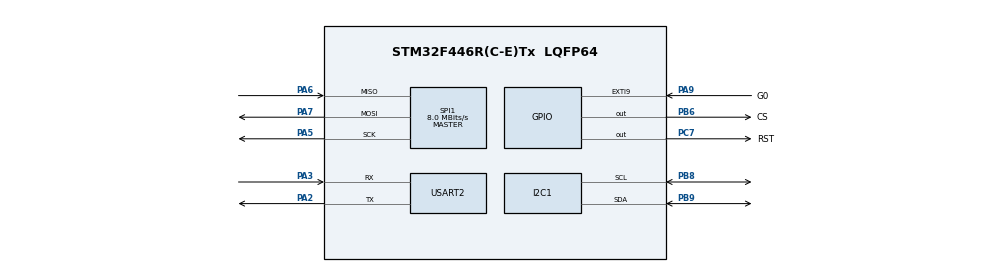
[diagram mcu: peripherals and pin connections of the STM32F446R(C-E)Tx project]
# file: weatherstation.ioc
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Dma.Request0=SPI1_TX
Dma.SPI1_TX.0.Direction=DMA_MEMORY_TO_PERIPH
Dma.SPI1_TX.0.FIFOMode=DMA_FIFOMODE_DISABLE
Dma.SPI1_TX.0.Instance=DMA2_Stream3
Dma.SPI1_TX.0.MemDataAlignment=DMA_MDATAALIGN_BYTE
Dma.SPI1_TX.0.MemInc=DMA_MINC_ENABLE
Dma.SPI1_TX.0.Mode=DMA_NORMAL
Dma.SPI1_TX.0.PeriphDataAlignment=DMA_PDATAALIGN_BYTE
Dma.SPI1_TX.0.PeriphInc=DMA_PINC_DISABLE
Dma.SPI1_TX.0.Priority=DMA_PRIORITY_LOW
Mcu.Family=STM32F4
Mcu.Name=STM32F446R(C-E)Tx
Mcu.Package=LQFP64
NVIC.DMA2_Stream3_IRQn=true\:0\:0\:false\:false\:true\:false\:true\:true
NVIC.EXTI9_5_IRQn=true\:5\:0\:true\:false\:true\:true\:true\:true
NVIC.PriorityGroup=NVIC_PRIORITYGROUP_4
NVIC.SPI1_IRQn=true\:0\:0\:false\:false\:true\:true\:true\:true
NVIC.TIM6_DAC_IRQn=true\:15\:0\:false\:false\:true\:false\:true\:true
NVIC.TimeBase=TIM6_DAC_IRQn
NVIC.TimeBaseIP=TIM6
PA2.Mode=Asynchronous
PA2.Signal=USART2_TX
PA3.Mode=Asynchronous
PA3.Signal=USART2_RX
PA5.Mode=Full_Duplex_Master
PA5.Signal=SPI1_SCK
PA6.Mode=Full_Duplex_Master
PA6.Signal=SPI1_MISO
PA7.Mode=Full_Duplex_Master
PA7.Signal=SPI1_MOSI
PA9.GPIO_Label=G0
PA9.Signal=GPXTI9
PB6.GPIO_Label=CS
PB6.PinState=GPIO_PIN_SET
PB6.Signal=GPIO_Output
PB8.Mode=I2C
PB8.Signal=I2C1_SCL
PB9.Mode=I2C
PB9.Signal=I2C1_SDA
PC7.GPIO_Label=RST
PC7.PinState=GPIO_PIN_SET
PC7.Signal=GPIO_Output
ProjectManager.HeapSize=0x200
ProjectManager.StackSize=0x400
ProjectManager.TargetToolchain=CMake
RCC.CortexFreq_Value=16000000
RCC.USBFreq_Value=96000000
RCC.VCOOutputFreq_Value=192000000
SPI1.CalculateBaudRate=8.0 MBits/s
SPI1.Direction=SPI_DIRECTION_2LINES
SPI1.Mode=SPI_MODE_MASTER
SPI1.VirtualType=VM_MASTER
USART2.VirtualMode=VM_ASYNC
VP_SYS_VS_tim6.Mode=TIM6
board=custom

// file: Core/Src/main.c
/* USER CODE BEGIN Header */
/**
  ******************************************************************************
  * @file           : main.c
  * @brief          : Main program body
  ******************************************************************************
  * @attention
  *
  * Copyright (c) 2026 STMicroelectronics.
  * All rights reserved.
  *
  * This software is licensed under terms that can be found in the LICENSE file
  * in the root directory of this software component.
  * If no LICENSE file comes with this software, it is provided AS-IS.
  *
  ******************************************************************************
  */
/* USER CODE END Header */
#include "main.h"

/* USER CODE BEGIN Includes */
#include "main_ws.h"
/* USER CODE END Includes */

I2C_HandleTypeDef hi2c1;

SPI_HandleTypeDef hspi1;
DMA_HandleTypeDef hdma_spi1_tx;

UART_HandleTypeDef huart2;

void SystemClock_Config(void);
static void MX_GPIO_Init(void);
static void MX_DMA_Init(void);
static void MX_I2C1_Init(void);
static void MX_USART2_UART_Init(void);
static void MX_SPI1_Init(void);

int main(void)
{

  /* MCU Configuration--------------------------------------------------------*/

  /* Reset of all peripherals, Initializes the Flash interface and the Systick. */
  HAL_Init();

  /* Configure the system clock */
  SystemClock_Config();

  /* Initialize all configured peripherals */
  MX_GPIO_Init();
  MX_DMA_Init();
  MX_I2C1_Init();
  MX_USART2_UART_Init();
  MX_SPI1_Init();
  /* USER CODE BEGIN 2 */
  main_ws();

  /* USER CODE END 2 */

  /* Infinite loop */
  while (1)
  {

  }
}

void SystemClock_Config(void)
{
  RCC_OscInitTypeDef RCC_OscInitStruct = {0};
  RCC_ClkInitTypeDef RCC_ClkInitStruct = {0};

  /** Configure the main internal regulator output voltage
  */
  __HAL_RCC_PWR_CLK_ENABLE();
  __HAL_PWR_VOLTAGESCALING_CONFIG(PWR_REGULATOR_VOLTAGE_SCALE3);

  /** Initializes the RCC Oscillators according to the specified parameters
  * in the RCC_OscInitTypeDef structure.
  */
  RCC_OscInitStruct.OscillatorType = RCC_OSCILLATORTYPE_HSI;
  RCC_OscInitStruct.HSIState = RCC_HSI_ON;
  RCC_OscInitStruct.HSICalibrationValue = RCC_HSICALIBRATION_DEFAULT;
  RCC_OscInitStruct.PLL.PLLState = RCC_PLL_NONE;
  if (HAL_RCC_OscConfig(&RCC_OscInitStruct) != HAL_OK)
  {
    Error_Handler();
  }

  /** Initializes the CPU, AHB and APB buses clocks
  */
  RCC_ClkInitStruct.ClockType = RCC_CLOCKTYPE_HCLK|RCC_CLOCKTYPE_SYSCLK
                              |RCC_CLOCKTYPE_PCLK1|RCC_CLOCKTYPE_PCLK2;
  RCC_ClkInitStruct.SYSCLKSource = RCC_SYSCLKSOURCE_HSI;
  RCC_ClkInitStruct.AHBCLKDivider = RCC_SYSCLK_DIV1;
  RCC_ClkInitStruct.APB1CLKDivider = RCC_HCLK_DIV1;
  RCC_ClkInitStruct.APB2CLKDivider = RCC_HCLK_DIV1;

  if (HAL_RCC_ClockConfig(&RCC_ClkInitStruct, FLASH_LATENCY_0) != HAL_OK)
  {
    Error_Handler();
  }
}

static void MX_I2C1_Init(void)
{

  hi2c1.Instance = I2C1;
  hi2c1.Init.ClockSpeed = 100000;
  hi2c1.Init.DutyCycle = I2C_DUTYCYCLE_2;
  hi2c1.Init.OwnAddress1 = 0;
  hi2c1.Init.AddressingMode = I2C_ADDRESSINGMODE_7BIT;
  hi2c1.Init.DualAddressMode = I2C_DUALADDRESS_DISABLE;
  hi2c1.Init.OwnAddress2 = 0;
  hi2c1.Init.GeneralCallMode = I2C_GENERALCALL_DISABLE;
  hi2c1.Init.NoStretchMode = I2C_NOSTRETCH_DISABLE;
  if (HAL_I2C_Init(&hi2c1) != HAL_OK)
  {
    Error_Handler();
  }

}

static void MX_SPI1_Init(void)
{

  /* SPI1 parameter configuration*/
  hspi1.Instance = SPI1;
  hspi1.Init.Mode = SPI_MODE_MASTER;
  hspi1.Init.Direction = SPI_DIRECTION_2LINES;
  hspi1.Init.DataSize = SPI_DATASIZE_8BIT;
  hspi1.Init.CLKPolarity = SPI_POLARITY_LOW;
  hspi1.Init.CLKPhase = SPI_PHASE_1EDGE;
  hspi1.Init.NSS = SPI_NSS_SOFT;
  hspi1.Init.BaudRatePrescaler = SPI_BAUDRATEPRESCALER_2;
  hspi1.Init.FirstBit = SPI_FIRSTBIT_MSB;
  hspi1.Init.TIMode = SPI_TIMODE_DISABLE;
  hspi1.Init.CRCCalculation = SPI_CRCCALCULATION_DISABLE;
  hspi1.Init.CRCPolynomial = 10;
  if (HAL_SPI_Init(&hspi1) != HAL_OK)
  {
    Error_Handler();
  }

}

static void MX_USART2_UART_Init(void)
{

  huart2.Instance = USART2;
  huart2.Init.BaudRate = 115200;
  huart2.Init.WordLength = UART_WORDLENGTH_8B;
  huart2.Init.StopBits = UART_STOPBITS_1;
  huart2.Init.Parity = UART_PARITY_NONE;
  huart2.Init.Mode = UART_MODE_TX_RX;
  huart2.Init.HwFlowCtl = UART_HWCONTROL_NONE;
  huart2.Init.OverSampling = UART_OVERSAMPLING_16;
  if (HAL_UART_Init(&huart2) != HAL_OK)
  {
    Error_Handler();
  }

}

static void MX_DMA_Init(void)
{

  /* DMA controller clock enable */
  __HAL_RCC_DMA2_CLK_ENABLE();

  /* DMA interrupt init */
  /* DMA2_Stream3_IRQn interrupt configuration */
  HAL_NVIC_SetPriority(DMA2_Stream3_IRQn, 0, 0);
  HAL_NVIC_EnableIRQ(DMA2_Stream3_IRQn);

}

static void MX_GPIO_Init(void)
{
  GPIO_InitTypeDef GPIO_InitStruct = {0};

  /* GPIO Ports Clock Enable */
  __HAL_RCC_GPIOA_CLK_ENABLE();
  __HAL_RCC_GPIOC_CLK_ENABLE();
  __HAL_RCC_GPIOB_CLK_ENABLE();

  /*Configure GPIO pin Output Level */
  HAL_GPIO_WritePin(RST_GPIO_Port, RST_Pin, GPIO_PIN_SET);

  /*Configure GPIO pin Output Level */
  HAL_GPIO_WritePin(CS_GPIO_Port, CS_Pin, GPIO_PIN_SET);

  /*Configure GPIO pin : RST_Pin */
  GPIO_InitStruct.Pin = RST_Pin;
  GPIO_InitStruct.Mode = GPIO_MODE_OUTPUT_PP;
  GPIO_InitStruct.Pull = GPIO_NOPULL;
  GPIO_InitStruct.Speed = GPIO_SPEED_FREQ_LOW;
  HAL_GPIO_Init(RST_GPIO_Port, &GPIO_InitStruct);

  /*Configure GPIO pin : G0_Pin */
  GPIO_InitStruct.Pin = G0_Pin;
  GPIO_InitStruct.Mode = GPIO_MODE_IT_RISING;
  GPIO_InitStruct.Pull = GPIO_NOPULL;
  HAL_GPIO_Init(G0_GPIO_Port, &GPIO_InitStruct);

  /*Configure GPIO pin : CS_Pin */
  GPIO_InitStruct.Pin = CS_Pin;
  GPIO_InitStruct.Mode = GPIO_MODE_OUTPUT_PP;
  GPIO_InitStruct.Pull = GPIO_NOPULL;
  GPIO_InitStruct.Speed = GPIO_SPEED_FREQ_LOW;
  HAL_GPIO_Init(CS_GPIO_Port, &GPIO_InitStruct);

  /* EXTI interrupt init*/
  HAL_NVIC_SetPriority(EXTI9_5_IRQn, 5, 0);
  HAL_NVIC_EnableIRQ(EXTI9_5_IRQn);

}

void HAL_TIM_PeriodElapsedCallback(TIM_HandleTypeDef *htim)
{
  if (htim->Instance == TIM6)
  {
    HAL_IncTick();
  }
}

void Error_Handler(void)
{
  __disable_irq();
  while (1)
  {
  }
}
